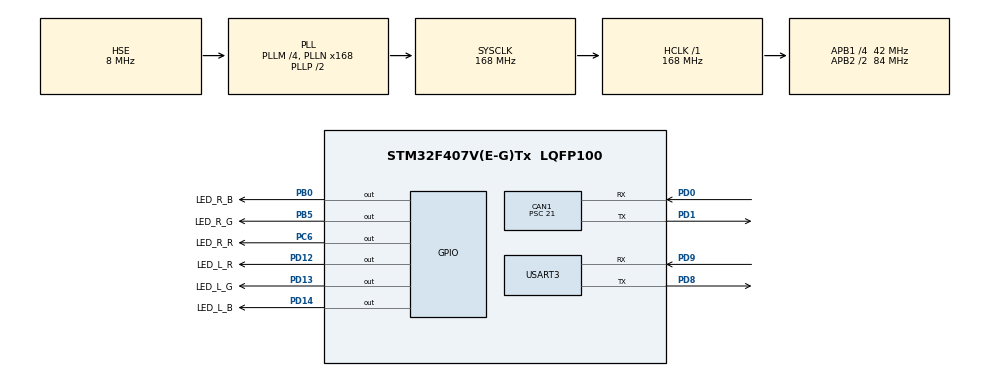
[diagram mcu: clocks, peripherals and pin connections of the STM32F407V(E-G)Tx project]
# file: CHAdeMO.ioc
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CAN1.BS1=CAN_BS1_14TQ
CAN1.BS2=CAN_BS2_5TQ
CAN1.CalculateBaudRate=100000
CAN1.CalculateTimeBit=10000
CAN1.CalculateTimeQuantum=500.0
CAN1.Prescaler=21
CAN1.SJW=CAN_SJW_1TQ
IWDG.Prescaler=IWDG_PRESCALER_4
IWDG.Reload=4000-1
Mcu.Family=STM32F4
Mcu.Name=STM32F407V(E-G)Tx
Mcu.Package=LQFP100
NVIC.CAN1_RX0_IRQn=true\:0\:0\:false\:false\:true\:true\:true\:true
NVIC.PriorityGroup=NVIC_PRIORITYGROUP_4
NVIC.RCC_IRQn=true\:0\:0\:false\:false\:true\:true\:false\:true
NVIC.TIM6_DAC_IRQn=true\:15\:0\:false\:false\:true\:false\:true\:true
NVIC.TIM7_IRQn=true\:0\:0\:false\:false\:true\:true\:true\:true
NVIC.TimeBase=TIM6_DAC_IRQn
NVIC.TimeBaseIP=TIM6
NVIC.USART3_IRQn=true\:0\:0\:false\:false\:true\:true\:true\:true
PA13.Mode=Serial_Wire
PA13.Signal=SYS_JTMS-SWDIO
PA14.Mode=Serial_Wire
PA14.Signal=SYS_JTCK-SWCLK
PB0.GPIO_Label=LED_R_B
PB0.PinState=GPIO_PIN_SET
PB0.Signal=GPIO_Output
PB5.GPIO_Label=LED_R_G
PB5.PinState=GPIO_PIN_RESET
PB5.Signal=GPIO_Output
PC6.GPIO_Label=LED_R_R
PC6.PinState=GPIO_PIN_SET
PC6.Signal=GPIO_Output
PD0.Mode=CAN_Activate
PD0.Signal=CAN1_RX
PD1.Mode=CAN_Activate
PD1.Signal=CAN1_TX
PD12.GPIO_Label=LED_L_R
PD12.GPIO_PuPd=GPIO_NOPULL
PD12.PinState=GPIO_PIN_SET
PD12.Signal=GPIO_Output
PD13.GPIO_Label=LED_L_G
PD13.GPIO_PuPd=GPIO_NOPULL
PD13.PinState=GPIO_PIN_SET
PD13.Signal=GPIO_Output
PD14.GPIO_Label=LED_L_B
PD14.GPIO_PuPd=GPIO_NOPULL
PD14.PinState=GPIO_PIN_SET
PD14.Signal=GPIO_Output
PD8.Mode=Asynchronous
PD8.Signal=USART3_TX
PD9.Mode=Asynchronous
PD9.Signal=USART3_RX
PH0-OSC_IN.Mode=HSE-External-Oscillator
PH0-OSC_IN.Signal=RCC_OSC_IN
PH1-OSC_OUT.Mode=HSE-External-Oscillator
PH1-OSC_OUT.Signal=RCC_OSC_OUT
ProjectManager.HeapSize=0x200
ProjectManager.StackSize=0x400
ProjectManager.TargetToolchain=STM32CubeIDE
RCC.48MHZClocksFreq_Value=84000000
RCC.AHBFreq_Value=168000000
RCC.APB1CLKDivider=RCC_HCLK_DIV4
RCC.APB1Freq_Value=42000000
RCC.APB1TimFreq_Value=84000000
RCC.APB2CLKDivider=RCC_HCLK_DIV2
RCC.APB2Freq_Value=84000000
RCC.APB2TimFreq_Value=168000000
RCC.CortexFreq_Value=168000000
RCC.HCLKFreq_Value=168000000
RCC.HSE_VALUE=8000000
RCC.HSI_VALUE=16000000
RCC.LSE_VALUE=32768
RCC.PLLM=4
RCC.PLLN=168
RCC.PLLSourceVirtual=RCC_PLLSOURCE_HSE
RCC.SYSCLKFreq_VALUE=168000000
RCC.SYSCLKSource=RCC_SYSCLKSOURCE_PLLCLK
RCC.VCOOutputFreq_Value=336000000
TIM7.Period=1000-1
TIM7.Prescaler=84-1
USART3.VirtualMode=VM_ASYNC
VP_IWDG_VS_IWDG.Mode=IWDG_Activate
VP_SYS_VS_tim6.Mode=TIM6
VP_TIM7_VS_ClockSourceINT.Mode=Enable_Timer
board=custom

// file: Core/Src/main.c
/* USER CODE BEGIN Header */
/**
 ******************************************************************************
 * @file           : main.c
 * @brief          : Main program body
 ******************************************************************************
 * @attention
 *
 * Copyright (c) 2023 STMicroelectronics.
 * All rights reserved.
 *
 * This software is licensed under terms that can be found in the LICENSE file
 * in the root directory of this software component.
 * If no LICENSE file comes with this software, it is provided AS-IS.
 *
 ******************************************************************************
 */
/* USER CODE END Header */
#include "main.h"
#include "can.h"
#include "iwdg.h"
#include "tim.h"
#include "usart.h"
#include "gpio.h"

/* USER CODE BEGIN Includes */
#include <stdio.h>

#include "koolcharge.h"
/* USER CODE END Includes */

void SystemClock_Config(void);
/* USER CODE BEGIN PFP */
int _write(int file, char *ptr, int len) {
    if (HAL_UART_Transmit(&huart3, (uint8_t *)ptr, len, 10) == HAL_OK)
        return len;
    return -1;
}

/* USER CODE END PFP */

int main(void)
{

  /* MCU Configuration--------------------------------------------------------*/

  /* Reset of all peripherals, Initializes the Flash interface and the Systick. */
  HAL_Init();

  /* Configure the system clock */
  SystemClock_Config();

  /* Initialize all configured peripherals */
  MX_GPIO_Init();
  MX_TIM7_Init();
  MX_IWDG_Init();
  MX_USART3_UART_Init();
  MX_CAN1_Init();
  /* USER CODE BEGIN 2 */
    HAL_TIM_Base_Start_IT(&htim7);
  /* USER CODE END 2 */

  /* Infinite loop */
  /* USER CODE BEGIN WHILE */
    printf("init complete before mainProcess\n");
    while (1) {
        mainProcess();
    /* USER CODE END WHILE */

    }
}

void SystemClock_Config(void)
{
  RCC_OscInitTypeDef RCC_OscInitStruct = {0};
  RCC_ClkInitTypeDef RCC_ClkInitStruct = {0};

  /** Configure the main internal regulator output voltage
  */
  __HAL_RCC_PWR_CLK_ENABLE();
  __HAL_PWR_VOLTAGESCALING_CONFIG(PWR_REGULATOR_VOLTAGE_SCALE1);

  /** Initializes the RCC Oscillators according to the specified parameters
  * in the RCC_OscInitTypeDef structure.
  */
  RCC_OscInitStruct.OscillatorType = RCC_OSCILLATORTYPE_LSI|RCC_OSCILLATORTYPE_HSE;
  RCC_OscInitStruct.HSEState = RCC_HSE_ON;
  RCC_OscInitStruct.LSIState = RCC_LSI_ON;
  RCC_OscInitStruct.PLL.PLLState = RCC_PLL_ON;
  RCC_OscInitStruct.PLL.PLLSource = RCC_PLLSOURCE_HSE;
  RCC_OscInitStruct.PLL.PLLM = 4;
  RCC_OscInitStruct.PLL.PLLN = 168;
  RCC_OscInitStruct.PLL.PLLP = RCC_PLLP_DIV2;
  RCC_OscInitStruct.PLL.PLLQ = 4;
  if (HAL_RCC_OscConfig(&RCC_OscInitStruct) != HAL_OK)
  {
    Error_Handler();
  }

  /** Initializes the CPU, AHB and APB buses clocks
  */
  RCC_ClkInitStruct.ClockType = RCC_CLOCKTYPE_HCLK|RCC_CLOCKTYPE_SYSCLK
                              |RCC_CLOCKTYPE_PCLK1|RCC_CLOCKTYPE_PCLK2;
  RCC_ClkInitStruct.SYSCLKSource = RCC_SYSCLKSOURCE_PLLCLK;
  RCC_ClkInitStruct.AHBCLKDivider = RCC_SYSCLK_DIV1;
  RCC_ClkInitStruct.APB1CLKDivider = RCC_HCLK_DIV4;
  RCC_ClkInitStruct.APB2CLKDivider = RCC_HCLK_DIV2;

  if (HAL_RCC_ClockConfig(&RCC_ClkInitStruct, FLASH_LATENCY_5) != HAL_OK)
  {
    Error_Handler();
  }
}

void HAL_TIM_PeriodElapsedCallback(TIM_HandleTypeDef *htim)
{
  if (htim->Instance == TIM6) {
    HAL_IncTick();
  }
  /* USER CODE BEGIN Callback 1 */
    if (htim->Instance == TIM7) {
        onCounterMS();   // 1ms tick
        onCounterSEC();  // 1sec tock
    }
  /* USER CODE END Callback 1 */
}

void Error_Handler(void)
{
    __disable_irq();
    while (1) {
    }
}
